# STM32L052xx register map
File version: 1.0
Registers are 32-bit, read-write, reset 0x0 unless marked. A register's access mark holds for its fields unless they carry their own. Offsets are from the block's base; [hi:lo] are bit positions; {n}, {i} and the like mark numbered series; 'fields as' and 'values as' point back to an identical list.

## EXTI — External Interrupt/Event Controller
Base 0x40010400
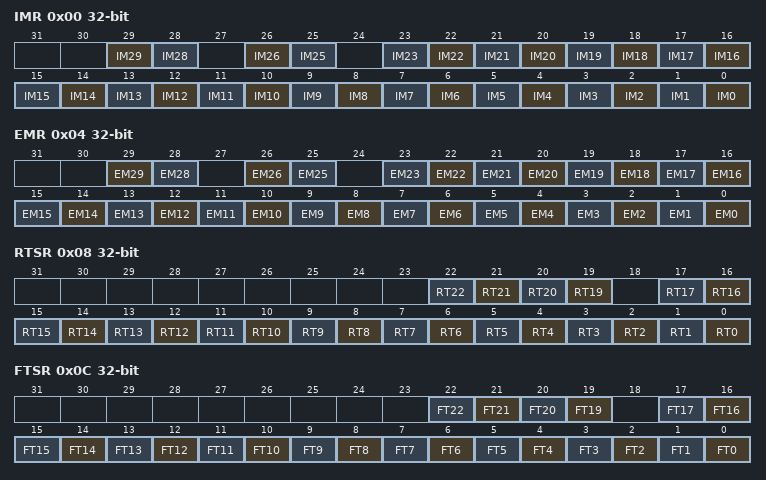
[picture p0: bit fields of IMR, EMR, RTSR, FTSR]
0x00 IMR — EXTI Interrupt mask register
  [29] IM29 — Interrupt Mask on line 29
  [28] IM28 — Interrupt Mask on line 28
  [26] IM26 — Interrupt Mask on line 26
  [25] IM25 — Interrupt Mask on line 25
  [n] IM{n} (n=0..23) — Interrupt Mask on line {n}
0x04 EMR — EXTI Event mask register
  [29] EM29 — Event Mask on line 29
  [28] EM28 — Event Mask on line 28
  [26] EM26 — Event Mask on line 26
  [25] EM25 — Event Mask on line 25
  [n] EM{n} (n=0..23) — Event Mask on line {n}
0x08 RTSR — EXTI Rising trigger selection register
  [n] RT{n} (n=19..22) — Rising trigger event configuration bit of line {n}
  [n] RT{n} (n=0..17) — Rising trigger event configuration bit of line {n}
0x0C FTSR — EXTI Falling trigger selection register
  [n] FT{n} (n=19..22) — Falling trigger event configuration bit of line {n}
  [n] FT{n} (n=0..17) — Falling trigger event configuration bit of line {n}
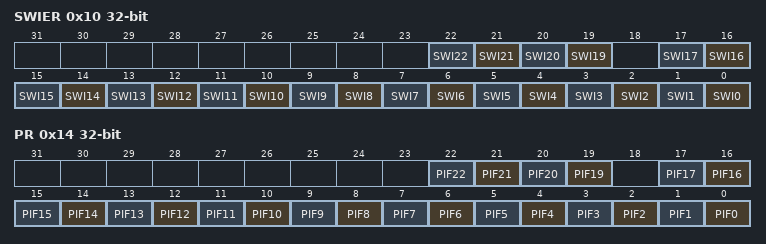
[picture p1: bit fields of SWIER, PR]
0x10 SWIER — EXTI Software interrupt event register
  [n] SWI{n} (n=19..22) — Software Interrupt on line {n}
  [n] SWI{n} (n=0..17) — Software Interrupt on line {n}
0x14 PR — EXTI Pending register
  [n] PIF{n} (n=19..22) — Pending bit {n}
  [n] PIF{n} (n=0..17) — Pending bit {n}

## FIREWALL — MIFARE Firewall
Base 0x40011C00
0x00 CSSA — Code Segment Start Address register
0x04 CSL — Code Segment Length register
0x08 NVDSSA — NON volatile data Segment Start Address register
0x0C NVDSL — NON volatile data Segment Length register
0x10 VDSSA — Volatile data Segment Start Address register
0x14 VDSL — Volatile data Segment Length register
0x18 LSSA — Library Segment Start Address register
0x1C LSL — Library Segment Length register
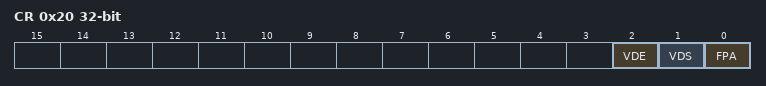
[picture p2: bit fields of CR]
0x20 CR — Configuration register
  [2] VDE — Volatile Data Execution
  [1] VDS — Volatile Data Sharing
  [0] FPA — Firewall Pre Arm

## DBGMCU — Debug MCU
Base 0x40015800
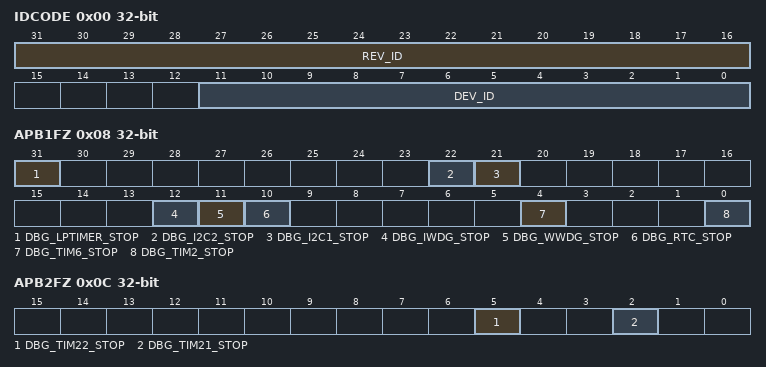
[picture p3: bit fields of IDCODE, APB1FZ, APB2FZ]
0x00 IDCODE — MCU device ID code
  [31:16] REV_ID — REV_ID[15:0] bits (Revision Identifier)
  [11:0] DEV_ID — Device Identifier
0x04 CR — Debug MCU configuration register
  [2:0] DBG — Debug mode mask
0x08 APB1FZ — Debug MCU APB1 freeze register
  [31] DBG_LPTIMER_STOP — LPTIM1 counter stopped when core is halted
  [22] DBG_I2C2_STOP — I2C2 SMBUS timeout mode stopped when Core is halted
  [21] DBG_I2C1_STOP — I2C1 SMBUS timeout mode stopped when Core is halted
  [12] DBG_IWDG_STOP — Debug Independent Watchdog stopped when Core is halted
  [11] DBG_WWDG_STOP — Debug Window Watchdog stopped when Core is halted
  [10] DBG_RTC_STOP — RTC Calendar frozen when core is halted
  [4] DBG_TIM6_STOP — TIM6 counter stopped when core is halted
  [0] DBG_TIM2_STOP — TIM2 counter stopped when core is halted
0x0C APB2FZ — Debug MCU APB2 freeze register
  [5] DBG_TIM22_STOP — TIM22 counter stopped when core is halted
  [2] DBG_TIM21_STOP — TIM21 counter stopped when core is halted

## DMA1
Base 0x40020000
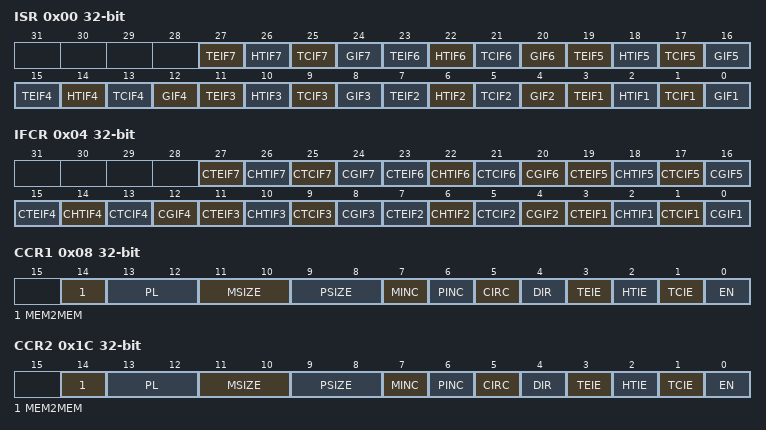
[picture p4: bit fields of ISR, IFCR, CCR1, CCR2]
0x00 ISR — DMA interrupt status register
  [4n-1] TEIF{n} (n=1..7) — Channel {n} Transfer Error flag
  [4n-2] HTIF{n} (n=1..7) — Channel {n} Half Transfer flag
  [4n-3] TCIF{n} (n=1..7) — Channel {n} Transfer Complete flag
  [4n-4] GIF{n} (n=1..7) — Channel {n} Global interrupt flag
0x04 IFCR — DMA interrupt flag clear register
  [4n-1] CTEIF{n} (n=1..7) — Channel {n} Transfer Error clear
  [4n-2] CHTIF{n} (n=1..7) — Channel {n} Half Transfer clear
  [4n-3] CTCIF{n} (n=1..7) — Channel {n} Transfer Complete clear
  [4n-4] CGIF{n} (n=1..7) — Channel {n} Global interrupt clear
0x08 CCR1 — DMA channel x configuration register
  [14] MEM2MEM — Memory to memory mode
  [13:12] PL — PL[1:0] bits(Channel Priority level)
  [11:10] MSIZE — MSIZE[1:0] bits (Memory size)
  [9:8] PSIZE — PSIZE[1:0] bits (Peripheral size)
  [7] MINC — Memory increment mode
  [6] PINC — Peripheral increment mode
  [5] CIRC — Circular mode
  [4] DIR — Data transfer direction
  [3] TEIE — Transfer error interrupt enable
  [2] HTIE — Half Transfer interrupt enable
  [1] TCIE — Transfer complete interrupt enable
  [0] EN — Channel enable
0x0C CNDTR1 — DMA channel x number of data register
  [15:0] NDT — Number of data to Transfer
0x10 CPAR1 — DMA channel x peripheral address register
  [31:0] PA — Peripheral Address
{0x0+0x14*i} CMAR{i} (i=1..7) — DMA channel x memory address register
  [31:0] MA — Memory Address
0x1C CCR2 — DMA channel x configuration register
  fields as CCR1
0x20 CNDTR2 — DMA channel x number of data register
  [15:0] NDT — Number of data to Transfer
0x24 CPAR2 — DMA channel x peripheral address register
  [31:0] PA — Peripheral Address
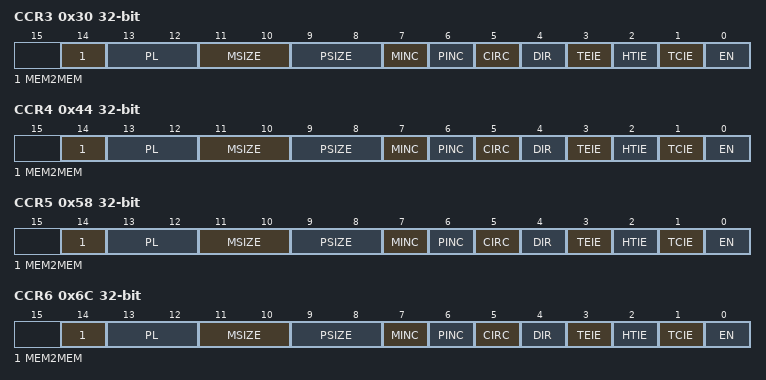
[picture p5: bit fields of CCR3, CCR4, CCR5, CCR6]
0x30 CCR3 — DMA channel x configuration register
  fields as CCR1
0x34 CNDTR3 — DMA channel x number of data register
  [15:0] NDT — Number of data to Transfer
0x38 CPAR3 — DMA channel x peripheral address register
  [31:0] PA — Peripheral Address
0x44 CCR4 — DMA channel x configuration register
  fields as CCR1
0x48 CNDTR4 — DMA channel x number of data register
  [15:0] NDT — Number of data to Transfer
0x4C CPAR4 — DMA channel x peripheral address register
  [31:0] PA — Peripheral Address
0x58 CCR5 — DMA channel x configuration register
  fields as CCR1
0x5C CNDTR5 — DMA channel x number of data register
  [15:0] NDT — Number of data to Transfer
0x60 CPAR5 — DMA channel x peripheral address register
  [31:0] PA — Peripheral Address
0x6C CCR6 — DMA channel x configuration register
  fields as CCR1
0x70 CNDTR6 — DMA channel x number of data register
  [15:0] NDT — Number of data to Transfer
0x74 CPAR6 — DMA channel x peripheral address register
  [31:0] PA — Peripheral Address
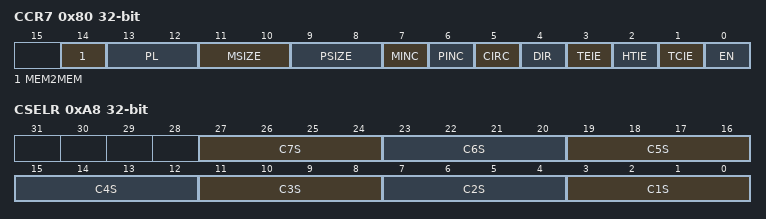
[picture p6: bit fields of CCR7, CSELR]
0x80 CCR7 — DMA channel x configuration register
  fields as CCR1
0x84 CNDTR7 — DMA channel x number of data register
  [15:0] NDT — Number of data to Transfer
0x88 CPAR7 — DMA channel x peripheral address register
  [31:0] PA — Peripheral Address
0xA8 CSELR — DMA channel selection register
  [4n-1:4n-4] C{n}S (n=1..7) — Channel {n} Selection
